# nrf51 register map
Vendor: Nordic Semiconductor; Series: nrf51; File version: 522
CPU: CM0 r3p1, little endian, no MPU, no FPU, 2 interrupt priority bits
Registers are 32-bit, read-write, reset 0x0 unless marked. A register's access mark holds for its fields unless they carry their own. Offsets are from the block's base; [hi:lo] are bit positions; {n}, {i} and the like mark numbered series; 'fields as' and 'values as' point back to an identical list.

## CLOCK — Clock control.
Base 0x40000000; alternate view of POWER
0x00 TASKS_HFCLKSTART wo — Start HFCLK clock source.
0x04 TASKS_HFCLKSTOP wo — Stop HFCLK clock source.
0x08 TASKS_LFCLKSTART wo — Start LFCLK clock source.
0x0C TASKS_LFCLKSTOP wo — Stop LFCLK clock source.
0x10 TASKS_CAL wo — Start calibration of LFCLK RC oscillator.
0x14 TASKS_CTSTART wo — Start calibration timer.
0x18 TASKS_CTSTOP wo — Stop calibration timer.
0x100 EVENTS_HFCLKSTARTED — HFCLK oscillator started.
0x104 EVENTS_LFCLKSTARTED — LFCLK oscillator started.
0x10C EVENTS_DONE — Calibration of LFCLK RC oscillator completed.
0x110 EVENTS_CTTO — Calibration timer timeout.
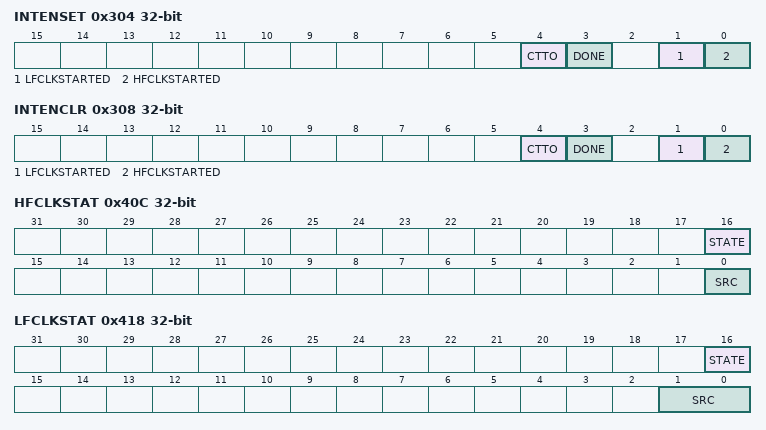
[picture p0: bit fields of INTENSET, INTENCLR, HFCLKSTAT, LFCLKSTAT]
0x304 INTENSET — Interrupt enable set register.
  [all] fields
    on read: 0=Disabled (Interrupt disabled.); 1=Enabled (Interrupt enabled.) | on write: 1=Set (Enable interrupt on write.)
  [4] CTTO — Enable interrupt on CTTO event.
  [3] DONE — Enable interrupt on DONE event.
  [1] LFCLKSTARTED — Enable interrupt on LFCLKSTARTED event.
  [0] HFCLKSTARTED — Enable interrupt on HFCLKSTARTED event.
0x308 INTENCLR — Interrupt enable clear register.
  [all] fields
    on read: 0=Disabled (Interrupt disabled.); 1=Enabled (Interrupt enabled.) | on write: 1=Clear (Disable interrupt on write.)
  [4] CTTO — Disable interrupt on CTTO event.
  [3] DONE — Disable interrupt on DONE event.
  [1] LFCLKSTARTED — Disable interrupt on LFCLKSTARTED event.
  [0] HFCLKSTARTED — Disable interrupt on HFCLKSTARTED event.
0x408 HFCLKRUN ro — Task HFCLKSTART trigger status.
  [0] STATUS
    0=NotTriggered (Task HFCLKSTART has not been triggered.); 1=Triggered (Task HFCLKSTART has been triggered.)
0x40C HFCLKSTAT ro — High frequency clock status.
  [16] STATE — State for the HFCLK.
    0=NotRunning (HFCLK clock not running.); 1=Running (HFCLK clock running.)
  [0] SRC — Active clock source for the HF clock.
    0=RC (Internal 16MHz RC oscillator running and generating the HFCLK clock.); 1=Xtal (External 16MHz/32MHz crystal oscillator running and generating the HFCLK clock.)
0x414 LFCLKRUN ro — Task LFCLKSTART triggered status.
  [0] STATUS
    0=NotTriggered (Task LFCLKSTART has not been triggered.); 1=Triggered (Task LFCLKSTART has been triggered.)
0x418 LFCLKSTAT ro — Low frequency clock status.
  [16] STATE — State for the LF clock.
    0=NotRunning (LFCLK clock not running.); 1=Running (LFCLK clock running.)
  [1:0] SRC — Active clock source for the LF clock.
    0=RC (Internal 32KiHz RC oscillator running and generating the LFCLK clock.); 1=Xtal (External 32KiHz crystal oscillator running and generating the LFCLK clock.); 2=Synth (Internal 32KiHz synthesizer from the HFCLK running and generating the LFCLK clock.)
0x41C LFCLKSRCCOPY ro — Clock source for the LFCLK clock, set when task LKCLKSTART is triggered.
  [1:0] SRC
    0=RC (Internal 32KiHz RC oscillator.); 1=Xtal (External 32KiHz crystal.); 2=Synth (Internal 32KiHz synthesizer from HFCLK system clock.)
0x518 LFCLKSRC — Clock source for the LFCLK clock.
  [1:0] SRC — Clock source.
    values as LFCLKSRCCOPY.SRC
0x538 CTIV — Calibration timer interval.
  [6:0] CTIV — Calibration timer interval in 0.25s resolution.
0x550 XTALFREQ reset 0xFFFFFFFF — Crystal frequency.
  [7:0] XTALFREQ — External Xtal frequency selection.
    255=16MHz xtal is used as source for the HFCLK oscillator; 0=32MHz xtal is used as source for the HFCLK oscillator

## MPU — Memory Protection Unit.
Base 0x40000000; alternate view of POWER
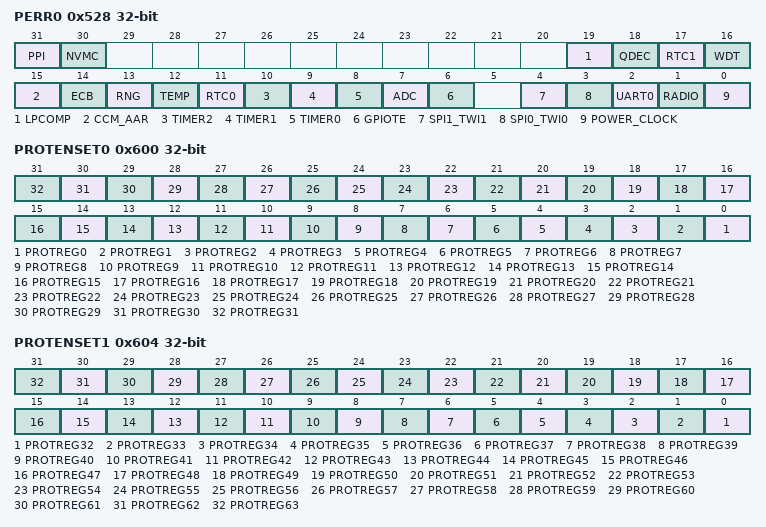
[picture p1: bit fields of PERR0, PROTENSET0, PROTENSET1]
0x528 PERR0 — Configuration of peripherals in mpu regions.
  [all] fields
    1=InRegion0 (Peripheral configured in region 0.); 0=InRegion1 (Peripheral configured in region 1.)
  [31] PPI — PPI region configuration.
  [30] NVMC — NVMC region configuration.
  [19] LPCOMP — LPCOMP region configuration.
  [18] QDEC — QDEC region configuration.
  [17] RTC1 — RTC1 region configuration.
  [16] WDT — WDT region configuration.
  [15] CCM_AAR — CCM and AAR region configuration.
  [14] ECB — ECB region configuration.
  [13] RNG — RNG region configuration.
  [12] TEMP — TEMP region configuration.
  [11] RTC0 — RTC0 region configuration.
  [10] TIMER2 — TIMER2 region configuration.
  [9] TIMER1 — TIMER1 region configuration.
  [8] TIMER0 — TIMER0 region configuration.
  [7] ADC — ADC region configuration.
  [6] GPIOTE — GPIOTE region configuration.
  [4] SPI1_TWI1 — SPI1 and TWI1 region configuration.
  [3] SPI0_TWI0 — SPI0 and TWI0 region configuration.
  [2] UART0 — UART0 region configuration.
  [1] RADIO — RADIO region configuration.
  [0] POWER_CLOCK — POWER_CLOCK region configuration.
0x52C RLENR0 — Length of RAM region 0.
0x600 PROTENSET0 — Erase and write protection bit enable set register.
  [all] fields
    on read: 0=Disabled (Protection disabled.); 1=Enabled (Protection enabled.) | on write: 1=Set (Enable protection on write.)
  [n] PROTREG{n} (n=0..31) — Protection enable for region {n}.
0x604 PROTENSET1 — Erase and write protection bit enable set register.
  [all] fields
    values as the fields of PROTENSET0
  [n-32] PROTREG{n} (n=32..63) — Protection enable for region {n}.
0x608 DISABLEINDEBUG reset 0x1 — Disable erase and write protection mechanism in debug mode.
  [0] DISABLEINDEBUG — Disable protection mechanism in debug mode.
    0=Enabled (Protection enabled.); 1=Disabled (Protection disabled.)
0x60C PROTBLOCKSIZE — Erase and write protection block size.
  [1:0] PROTBLOCKSIZE
    0=4k (Erase and write protection block size is 4k.)
